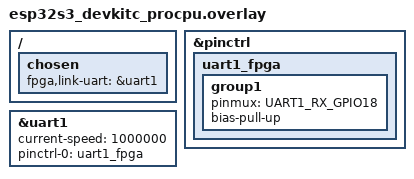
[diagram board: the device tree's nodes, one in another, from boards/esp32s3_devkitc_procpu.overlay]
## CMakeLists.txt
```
# Right half - primary.
cmake_minimum_required(VERSION 3.20.0)

find_package(Zephyr REQUIRED HINTS $ENV{ZEPHYR_BASE})
project(split_gyro_right)

target_sources(app PRIVATE
    src/main.c
    src/fpga_link.c
)
```

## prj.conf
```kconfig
# Right half - primary.
#
# Zephyr features this app needs switched on. Everything not listed here is
# left out of the build, which is why an embedded RTOS image stays small.

CONFIG_SERIAL=y
CONFIG_UART_INTERRUPT_DRIVEN=y

# The FPGA link fills a ring buffer from the uart ISR; a thread drains it.
CONFIG_RING_BUFFER=y

# printk/logging over the usb console
CONFIG_LOG=y
CONFIG_LOG_MODE_IMMEDIATE=y

CONFIG_MAIN_STACK_SIZE=4096
```

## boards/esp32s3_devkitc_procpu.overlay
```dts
/* Hardware description for the right half on an ESP32-S3-DevKitC-1.
 *
 * This is the device tree overlay: it says what hardware exists and how it is
 * wired, as data rather than as code. The C side asks for "the fpga link
 * uart" by name and receives it already configured. Moving to the final
 * board means editing this file, not the firmware.
 *
 * Same split as the FPGA side, where icestick.pcf says which pin is which and
 * the Verilog says what the logic does.
 */

&pinctrl {
	uart1_fpga: uart1_fpga {
		group1 {
			/* receive only - the FPGA has no uart_rx, so nothing is
			 * transmitted back on this link yet
			 */
			pinmux = <UART1_RX_GPIO18>;
			bias-pull-up;
		};
	};
};

&uart1 {
	status = "okay";
	current-speed = <1000000>;	/* matches CLKS_PER_BIT=12 at 12 MHz */
	pinctrl-0 = <&uart1_fpga>;
	pinctrl-names = "default";
};

/ {
	chosen {
		/* the application refers to this name, not to uart1 directly,
		 * so a different board can point it somewhere else
		 */
		fpga,link-uart = &uart1;
	};
};
```

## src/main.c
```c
/* Right half - primary.
 *
 * For now this does one thing: receive the FPGA's sensor packets and print
 * them, which closes validation item 3 from the firmware side. Mapping,
 * profiles, ESP-NOW and USB HID come next.
 *
 * Scale factors come from the ICM-45686 datasheet for the ranges the FPGA
 * configures: gyro +/-2000 dps is 16.4 LSB per deg/s, accel +/-8g is 4096
 * LSB per g.
 */

#include <zephyr/kernel.h>
#include <zephyr/device.h>
#include <zephyr/logging/log.h>
#include "fpga_link.h"

LOG_MODULE_REGISTER(main, LOG_LEVEL_INF);

#define GYRO_LSB_PER_DPS 16.4f
#define ACCEL_LSB_PER_G  4096.0f

/* Named in the device tree overlay rather than hardcoded, so a different
 * board can put the link on a different uart without touching this file.
 */
static const struct device *const fpga_uart =
	DEVICE_DT_GET(DT_CHOSEN(fpga_link_uart));

static const char *cart_name(uint8_t id)
{
	switch (id) {
	case 0x3: return "none";
	case 0x2: return "stick";
	case 0x1: return "dpad";
	default:  return "spare";
	}
}

int main(void)
{
	struct sensor_packet pkt = {0};
	uint32_t packets = 0;

	if (fpga_link_init(fpga_uart) != 0) {
		LOG_ERR("fpga link failed to start");
		return 0;
	}

	LOG_INF("right half up, listening to the fpga at 1 Mbaud");

	int64_t next_report = k_uptime_get() + 1000;

	while (1) {
		if (fpga_link_get(&pkt)) {
			packets++;
		}

		/* Report once a second. Printing at 200 Hz would be unreadable
		 * and would itself become the bottleneck.
		 */
		if (k_uptime_get() >= next_report) {
			next_report += 1000;

			LOG_INF("%4u Hz | accel %+6.2f %+6.2f %+6.2f g | "
				"gyro %+8.1f %+8.1f %+8.1f dps | "
				"cart %s/%s | %s | bad %u drop %u ovr %u",
				packets,
				(double)(pkt.accel_x / ACCEL_LSB_PER_G),
				(double)(pkt.accel_y / ACCEL_LSB_PER_G),
				(double)(pkt.accel_z / ACCEL_LSB_PER_G),
				(double)(pkt.gyro_x / GYRO_LSB_PER_DPS),
				(double)(pkt.gyro_y / GYRO_LSB_PER_DPS),
				(double)(pkt.gyro_z / GYRO_LSB_PER_DPS),
				cart_name(pkt.cart_a), cart_name(pkt.cart_b),
				pkt.calibrated ? "calibrated" : "uncalibrated",
				fpga_link_bad_checksums(),
				fpga_link_dropped(),
				fpga_link_overruns());

			packets = 0;
		}

		/* Yield so logging and the idle thread get a look in. The ISR
		 * keeps filling the ring regardless of what this thread does.
		 */
		k_sleep(K_MSEC(1));
	}

	return 0;
}
```

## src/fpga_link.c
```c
#include "fpga_link.h"
#include <zephyr/drivers/uart.h>
#include <zephyr/sys/ring_buffer.h>
#include <zephyr/logging/log.h>

LOG_MODULE_REGISTER(fpga_link, LOG_LEVEL_INF);

#define PACKET_LEN 21
#define SYNC0      0xAA
#define SYNC1      0x55

/* Two packets of slack. At 200 Hz the parser has 5 ms to drain a 21-byte
 * packet, so this only has to cover a scheduling hiccup, not a backlog.
 */
#define RX_RING_SIZE 64

static const struct device *uart_dev;

RING_BUF_DECLARE(rx_ring, RX_RING_SIZE);

static uint32_t bad_checksum;
static uint32_t dropped;
static uint32_t overruns;

/* ------------------------------------------------------------------ */
/* ISR: move bytes out of the uart fifo and into the ring, nothing else.
 * Parsing happens in thread context - an ISR should be short, and the
 * parser's state machine has no business running with interrupts masked.
 */
static void uart_isr(const struct device *dev, void *user_data)
{
	ARG_UNUSED(user_data);

	/* must be called once per isr before querying the irq state */
	uart_irq_update(dev);

	while (uart_irq_rx_ready(dev)) {
		uint8_t buf[32];
		int n = uart_fifo_read(dev, buf, sizeof(buf));

		if (n <= 0) {
			break;
		}

		/* If the ring is full the parser has fallen behind. Dropping
		 * here is correct: the checksum will reject whatever partial
		 * packet results, and the sync hunt resynchronises on the next
		 * one. Silently overwriting would corrupt a good packet instead.
		 */
		if (ring_buf_put(&rx_ring, buf, n) < (uint32_t)n) {
			overruns++;
		}
	}
}

int fpga_link_init(const struct device *uart)
{
	if (!device_is_ready(uart)) {
		LOG_ERR("uart device not ready");
		return -ENODEV;
	}

	uart_dev = uart;

	int err = uart_irq_callback_user_data_set(uart_dev, uart_isr, NULL);
	if (err) {
		LOG_ERR("could not set uart callback: %d", err);
		return err;
	}

	uart_irq_rx_enable(uart_dev);
	return 0;
}

/* ------------------------------------------------------------------ */
/* Thread side: hunt for the sync pattern, collect 21 bytes, validate. */

enum parse_state { WAIT_SYNC0, WAIT_SYNC1, COLLECT };

static enum parse_state state = WAIT_SYNC0;
static uint8_t  pkt[PACKET_LEN];
static size_t   idx;

static bool have_last_seq;
static uint8_t last_seq;

static int16_t be16(const uint8_t *p)
{
	return (int16_t)(((uint16_t)p[0] << 8) | p[1]);
}

static bool checksum_ok(void)
{
	uint8_t sum = 0;

	/* xor over everything between the sync bytes and the checksum itself */
	for (size_t i = 2; i < PACKET_LEN - 1; i++) {
		sum ^= pkt[i];
	}

	return sum == pkt[PACKET_LEN - 1];
}

static void decode(struct sensor_packet *o)
{
	o->seq = pkt[2];

	const uint8_t st = pkt[3];
	o->calibrated = st & 0x01;
	o->is_still   = st & 0x02;
	o->cart_a     = (st >> 2) & 0x03;
	o->cart_b     = (st >> 4) & 0x03;

	o->accel_x = be16(&pkt[4]);
	o->accel_y = be16(&pkt[6]);
	o->accel_z = be16(&pkt[8]);
	o->gyro_x  = be16(&pkt[10]);
	o->gyro_y  = be16(&pkt[12]);
	o->gyro_z  = be16(&pkt[14]);
	o->pitch   = be16(&pkt[16]);
	o->roll    = be16(&pkt[18]);

	/* The sequence counter exists so gaps are visible rather than silently
	 * smoothing over missing samples.
	 */
	if (have_last_seq && (uint8_t)(o->seq - last_seq) != 1) {
		dropped++;
	}
	last_seq = o->seq;
	have_last_seq = true;
}

bool fpga_link_get(struct sensor_packet *out)
{
	uint8_t b;

	while (ring_buf_get(&rx_ring, &b, 1) == 1) {
		switch (state) {
		case WAIT_SYNC0:
			if (b == SYNC0) {
				state = WAIT_SYNC1;
			}
			break;

		case WAIT_SYNC1:
			if (b == SYNC1) {
				state = COLLECT;
				idx = 2;
			} else if (b != SYNC0) {
				/* a second 0xAA could still be the real first
				 * sync byte, so only a third value resets
				 */
				state = WAIT_SYNC0;
			}
			break;

		case COLLECT:
			pkt[idx++] = b;
			if (idx == PACKET_LEN) {
				state = WAIT_SYNC0;
				if (checksum_ok()) {
					decode(out);
					return true;
				}
				/* false sync on an 0xAA 0x55 inside the payload */
				bad_checksum++;
			}
			break;
		}
	}

	return false;
}

uint32_t fpga_link_bad_checksums(void) { return bad_checksum; }
uint32_t fpga_link_dropped(void)       { return dropped; }
uint32_t fpga_link_overruns(void)      { return overruns; }
```

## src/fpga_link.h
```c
/* Receives the sensor packet the FPGA streams over uart.
 *
 * Packet, 21 bytes, as built by fpga/uart_tx_rx/sensor_packet.v:
 *
 *   0xAA 0x55 | seq | status | 12 sensor bytes | 4 angle bytes | xor
 *
 * Status byte:  [0] calibrated  [1] is_still  [3:2] cart_a  [5:4] cart_b
 * A receptacle id of 0b11 means nothing is inserted. The right half has one
 * receptacle, so cart_b always reads 0b11 there.
 *
 * Multi-byte fields are big endian. Note this is the opposite of how the
 * ICM-45686 returns them on the wire - the RTL already swaps them, so by the
 * time a packet reaches here everything is in the conventional order.
 *
 * A uart stream has no packet boundaries, so the receiver cannot simply read
 * 21 bytes at a time. Start mid-packet and every read after it is offset by
 * the same few bytes forever, producing values that look plausible and are
 * completely wrong. Hence the sync hunt, and the checksum before trusting
 * anything.
 */

#ifndef FPGA_LINK_H
#define FPGA_LINK_H

#include <zephyr/kernel.h>
#include <zephyr/device.h>

#define CART_NONE 0x3  /* 0b11 - nothing in the receptacle */

struct sensor_packet {
	uint8_t seq;
	bool    calibrated;	/* gyro bias has been learned */
	bool    is_still;	/* controller currently stationary */
	uint8_t cart_a;		/* receptacle ids, CART_NONE if empty */
	uint8_t cart_b;

	int16_t accel_x, accel_y, accel_z;
	int16_t gyro_x,  gyro_y,  gyro_z;
	int16_t pitch,   roll;	/* zero until the filter is on the FPGA */
};

/* Start receiving. The uart ISR fills a ring buffer; fpga_link_get drains it.
 * Returns 0 on success, negative errno otherwise.
 */
int fpga_link_init(const struct device *uart);

/* Non-blocking. Returns true and fills out when a whole, checksum-valid
 * packet is ready.
 */
bool fpga_link_get(struct sensor_packet *out);

/* Diagnostics. A rising bad-checksum count usually means a baud mismatch or
 * a noisy link; rising drops mean packets are being lost upstream.
 */
uint32_t fpga_link_bad_checksums(void);
uint32_t fpga_link_dropped(void);
uint32_t fpga_link_overruns(void);

#endif /* FPGA_LINK_H */
```
